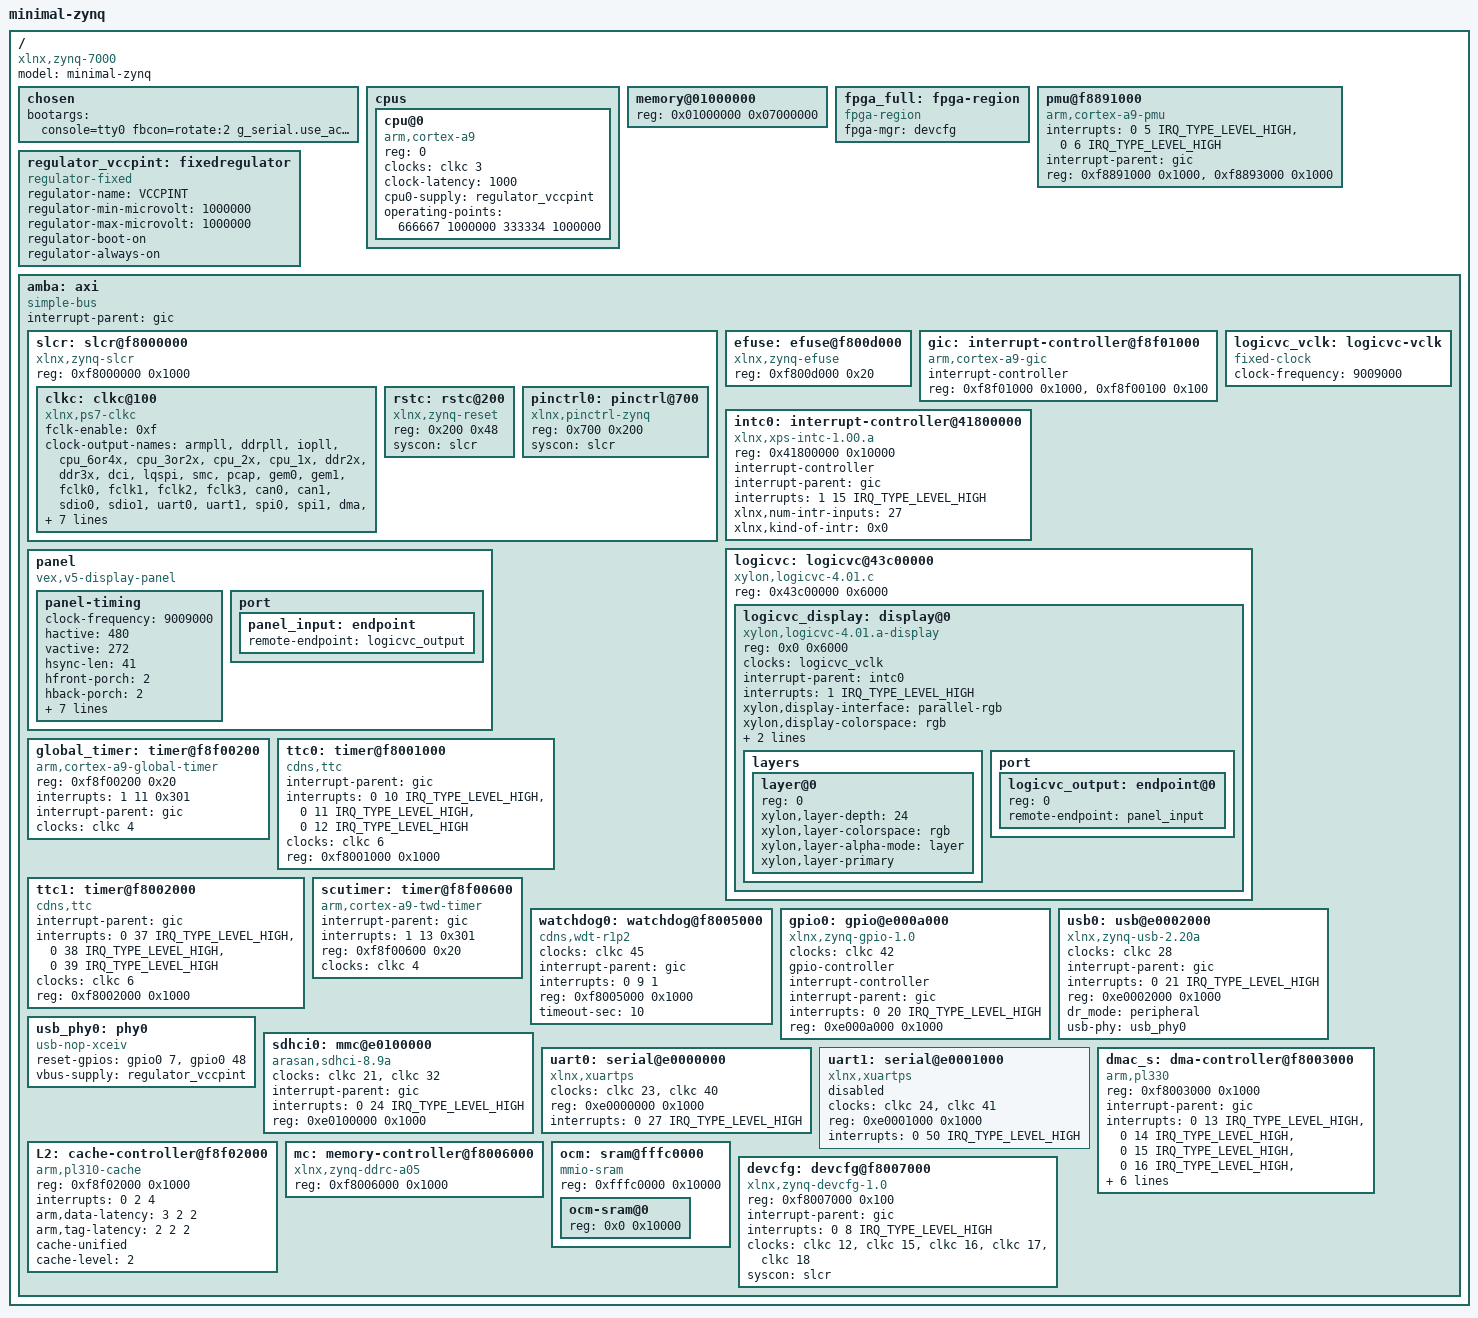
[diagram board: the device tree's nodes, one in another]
/dts-v1/;

#include <dt-bindings/gpio/gpio.h>
#include <dt-bindings/interrupt-controller/irq.h>

/ {
	compatible = "xlnx,zynq-7000";
	#address-cells = <1>;
	#size-cells = <1>;
	model = "minimal-zynq";

	chosen {
		bootargs = "console=tty0 fbcon=rotate:2 g_serial.use_acm=1 root=/dev/ram0 rw";
	};

	cpus {
		#address-cells = <1>;
		#size-cells = <0>;

		cpu@0 {
			device_type = "cpu";
			compatible = "arm,cortex-a9";
			reg = <0>;
			clocks = <&clkc 3>;
			clock-latency = <1000>;
			cpu0-supply = <&regulator_vccpint>;
			operating-points = <
								/* kHz    uV */
								666667 1000000
								333334 1000000>;
		};
	};

	memory@01000000 {
		device_type = "memory";
		reg = <0x01000000 0x07000000>;
	};

	fpga_full: fpga-region {
		compatible = "fpga-region";
		fpga-mgr = <&devcfg>;
		#address-cells = <1>;
		#size-cells = <1>;
		ranges;
	};

	pmu@f8891000 {
		compatible = "arm,cortex-a9-pmu";
		interrupts = <0 5 IRQ_TYPE_LEVEL_HIGH>, <0 6 IRQ_TYPE_LEVEL_HIGH>;
		interrupt-parent = <&gic>;
		reg = <0xf8891000 0x1000>,
			  <0xf8893000 0x1000>;
	};

	regulator_vccpint: fixedregulator {
		compatible = "regulator-fixed";
		regulator-name = "VCCPINT";
		regulator-min-microvolt = <1000000>;
		regulator-max-microvolt = <1000000>;
		regulator-boot-on;
		regulator-always-on;
	};

	amba: axi {
		bootph-all;
		compatible = "simple-bus";
		#address-cells = <1>;
		#size-cells = <1>;
		interrupt-parent = <&gic>;
		ranges;

		slcr: slcr@f8000000 {
			bootph-all;
			#address-cells = <1>;
			#size-cells = <1>;
			compatible = "xlnx,zynq-slcr", "syscon", "simple-mfd";
			reg = <0xf8000000 0x1000>;
			ranges;

			clkc: clkc@100 {
				bootph-all;
				#clock-cells = <1>;
				compatible = "xlnx,ps7-clkc";
				fclk-enable = <0xf>;
				clock-output-names = "armpll", "ddrpll", "iopll", "cpu_6or4x",
									 "cpu_3or2x", "cpu_2x", "cpu_1x", "ddr2x",
									 "ddr3x", "dci", "lqspi", "smc", "pcap", "gem0",
									 "gem1", "fclk0", "fclk1", "fclk2", "fclk3",
									 "can0", "can1", "sdio0", "sdio1", "uart0",
									 "uart1", "spi0", "spi1", "dma", "usb0_aper",
									 "usb1_aper", "gem0_aper", "gem1_aper",
									 "sdio0_aper", "sdio1_aper", "spi0_aper",
									 "spi1_aper", "can0_aper", "can1_aper",
									 "i2c0_aper", "i2c1_aper", "uart0_aper",
									 "uart1_aper", "gpio_aper", "lqspi_aper",
									 "smc_aper", "swdt", "dbg_trc", "dbg_apb";
				reg = <0x100 0x100>;
			};

			rstc: rstc@200 {
				compatible = "xlnx,zynq-reset";
				reg = <0x200 0x48>;
				#reset-cells = <1>;
				syscon = <&slcr>;
			};

			pinctrl0: pinctrl@700 {
				compatible = "xlnx,pinctrl-zynq";
				reg = <0x700 0x200>;
				syscon = <&slcr>;
			};
		};

		efuse: efuse@f800d000 {
			compatible = "xlnx,zynq-efuse";
			reg = <0xf800d000 0x20>;
		};

		gic: interrupt-controller@f8f01000 {
			compatible = "arm,cortex-a9-gic";
			#interrupt-cells = <3>;
			interrupt-controller;
			reg = <0xf8f01000 0x1000>,
				  <0xf8f00100 0x100>;
		};

		intc0: interrupt-controller@41800000 {
			compatible = "xlnx,xps-intc-1.00.a";
			reg = <0x41800000 0x10000>;

			interrupt-controller;
			#interrupt-cells = <2>;

			interrupt-parent = <&gic>;
			// PPI 31 (- 16)
			interrupts = <1 15 IRQ_TYPE_LEVEL_HIGH>;

			// 21 XUartLites, 1 XTmrCtr, some touchscreen peripheral are the known ones, but evidently there are more
			xlnx,num-intr-inputs = <27>; // 24 for INTC 1
			// XIntc[0].Config.AckBeforeService & 0x7FFFFFF = 0x0
			xlnx,kind-of-intr = <0x0>;
		};

		logicvc_vclk: logicvc-vclk {
			compatible = "fixed-clock";
			#clock-cells = <0>;
			// PixelClock=9009
			clock-frequency = <9009000>;
		};

		logicvc: logicvc@43c00000 {
			compatible = "xylon,logicvc-4.01.c", "syscon", "simple-mfd";
			reg = <0x43c00000 0x6000>;

			#address-cells = <1>;
			#size-cells = <1>;

			logicvc_display: display@0 {
				compatible = "xylon,logicvc-4.01.a-display";
				reg = <0x0 0x6000>;

				clocks = <&logicvc_vclk>;
				clock-names = "vclk";

				interrupt-parent = <&intc0>;
				interrupts = <1 IRQ_TYPE_LEVEL_HIGH>;

				xylon,display-interface = "parallel-rgb";
				xylon,display-colorspace = "rgb";
				xylon,display-depth = <24>;
				xylon,row-stride = <512>;

				layers {
					#address-cells = <1>;
					#size-cells = <0>;

					layer@0 {
						reg = <0>;
						xylon,layer-depth = <24>;
						xylon,layer-colorspace = "rgb";
						xylon,layer-alpha-mode = "layer";
						xylon,layer-primary;
					};
				};

				port {
					#address-cells = <1>;
					#size-cells = <0>;

					logicvc_output: endpoint@0 {
						reg = <0>;
						remote-endpoint = <&panel_input>;
					};
				};
			};
		};

		panel: panel {
			compatible = "vex,v5-display-panel", "panel-dpi";

			panel-timing {
				clock-frequency = <9009000>;
				hactive = <480>;
				vactive = <272>;
				hsync-len = <41>;
				hfront-porch = <2>;
				hback-porch = <2>;
				vsync-len = <10>;
				vfront-porch = <2>;
				vback-porch = <2>;

				// these are best-effort guesses
				hsync-active = <1>;
				vsync-active = <1>;
				de-active = <1>;
				pixelclk-active = <0>;
			};

			port {
				panel_input: endpoint {
					remote-endpoint = <&logicvc_output>;
				};
			};
		};

		global_timer: timer@f8f00200 {
			compatible = "arm,cortex-a9-global-timer";
			reg = <0xf8f00200 0x20>;
			interrupts = <1 11 0x301>;
			interrupt-parent = <&gic>;
			clocks = <&clkc 4>;
		};

		ttc0: timer@f8001000 {
			interrupt-parent = <&gic>;
			interrupts = <0 10 IRQ_TYPE_LEVEL_HIGH>, <0 11 IRQ_TYPE_LEVEL_HIGH>,
						 <0 12 IRQ_TYPE_LEVEL_HIGH>;
			compatible = "cdns,ttc";
			clocks = <&clkc 6>;
			reg = <0xf8001000 0x1000>;
		};

		ttc1: timer@f8002000 {
			interrupt-parent = <&gic>;
			interrupts = <0 37 IRQ_TYPE_LEVEL_HIGH>, <0 38 IRQ_TYPE_LEVEL_HIGH>,
						 <0 39 IRQ_TYPE_LEVEL_HIGH>;
			compatible = "cdns,ttc";
			clocks = <&clkc 6>;
			reg = <0xf8002000 0x1000>;
		};

		scutimer: timer@f8f00600 {
			bootph-all;
			interrupt-parent = <&gic>;
			interrupts = <1 13 0x301>; /* GIC id 29 */
			compatible = "arm,cortex-a9-twd-timer";
			reg = <0xf8f00600 0x20>;
			clocks = <&clkc 4>;
		};

		watchdog0: watchdog@f8005000 {
			clocks = <&clkc 45>;
			compatible = "cdns,wdt-r1p2";
			interrupt-parent = <&gic>;
			interrupts = <0 9 1>;
			reg = <0xf8005000 0x1000>;
			timeout-sec = <10>;
		};

		gpio0: gpio@e000a000 {
			compatible = "xlnx,zynq-gpio-1.0";
			#gpio-cells = <2>;
			clocks = <&clkc 42>;
			gpio-controller;
			interrupt-controller;
			#interrupt-cells = <2>;
			interrupt-parent = <&gic>;
			interrupts = <0 20 IRQ_TYPE_LEVEL_HIGH>;
			reg = <0xe000a000 0x1000>;
		};

		usb0: usb@e0002000 {
			compatible = "xlnx,zynq-usb-2.20a", "chipidea,usb2";
			clocks = <&clkc 28>;
			interrupt-parent = <&gic>;
			interrupts = <0 21 IRQ_TYPE_LEVEL_HIGH>;
			reg = <0xe0002000 0x1000>;
			status = "okay";
			dr_mode = "peripheral";
			usb-phy = <&usb_phy0>;
		};

		usb_phy0: phy0 {
			compatible = "usb-nop-xceiv";
			#phy-cells = <0>;
			reset-gpios = <&gpio0 7 GPIO_ACTIVE_HIGH>, <&gpio0 48 GPIO_ACTIVE_HIGH>;
			vbus-supply = <&regulator_vccpint>;
		};

		sdhci0: mmc@e0100000 {
			compatible = "arasan,sdhci-8.9a";
			status = "okay";
			clock-names = "clk_xin", "clk_ahb";
			clocks = <&clkc 21>, <&clkc 32>;
			interrupt-parent = <&gic>;
			interrupts = <0 24 IRQ_TYPE_LEVEL_HIGH>;
			reg = <0xe0100000 0x1000>;
		};

		uart0: serial@e0000000 {
			compatible = "xlnx,xuartps", "cdns,uart-r1p8";
			status = "okay";
			clocks = <&clkc 23>, <&clkc 40>;
			clock-names = "uart_clk", "pclk";
			reg = <0xe0000000 0x1000>;
			interrupts = <0 27 IRQ_TYPE_LEVEL_HIGH>;
		};

		uart1: serial@e0001000 {
			compatible = "xlnx,xuartps", "cdns,uart-r1p8";
			status = "disabled";
			clocks = <&clkc 24>, <&clkc 41>;
			clock-names = "uart_clk", "pclk";
			reg = <0xe0001000 0x1000>;
			interrupts = <0 50 IRQ_TYPE_LEVEL_HIGH>;
		};

		dmac_s: dma-controller@f8003000 {
			compatible = "arm,pl330", "arm,primecell";
			reg = <0xf8003000 0x1000>;
			interrupt-parent = <&gic>;
			/*
			 * interrupt-names = "abort", "dma0", "dma1", "dma2", "dma3",
			 * "dma4", "dma5", "dma6", "dma7";
			 */
			interrupts = <0 13 IRQ_TYPE_LEVEL_HIGH>,
						 <0 14 IRQ_TYPE_LEVEL_HIGH>, <0 15 IRQ_TYPE_LEVEL_HIGH>,
						 <0 16 IRQ_TYPE_LEVEL_HIGH>, <0 17 IRQ_TYPE_LEVEL_HIGH>,
						 <0 40 IRQ_TYPE_LEVEL_HIGH>, <0 41 IRQ_TYPE_LEVEL_HIGH>,
						 <0 42 IRQ_TYPE_LEVEL_HIGH>, <0 43 IRQ_TYPE_LEVEL_HIGH>;
			#dma-cells = <1>;
			clocks = <&clkc 27>;
			clock-names = "apb_pclk";
		};

		L2: cache-controller@f8f02000 {
			compatible = "arm,pl310-cache";
			reg = <0xf8f02000 0x1000>;
			interrupts = <0 2 4>;
			arm,data-latency = <3 2 2>;
			arm,tag-latency = <2 2 2>;
			cache-unified;
			cache-level = <2>;
		};

		mc: memory-controller@f8006000 {
			compatible = "xlnx,zynq-ddrc-a05";
			reg = <0xf8006000 0x1000>;
		};

		ocm: sram@fffc0000 {
			compatible = "mmio-sram";
			reg = <0xfffc0000 0x10000>;
			#address-cells = <1>;
			#size-cells = <1>;
			ranges = <0 0xfffc0000 0x10000>;

			ocm-sram@0 {
				reg = <0x0 0x10000>;
			};
		};

		devcfg: devcfg@f8007000 {
			compatible = "xlnx,zynq-devcfg-1.0";
			reg = <0xf8007000 0x100>;
			interrupt-parent = <&gic>;
			interrupts = <0 8 IRQ_TYPE_LEVEL_HIGH>;
			clocks = <&clkc 12>, <&clkc 15>, <&clkc 16>, <&clkc 17>, <&clkc 18>;
			clock-names = "ref_clk", "fclk0", "fclk1", "fclk2", "fclk3";
			syscon = <&slcr>;
		};
	};
};
